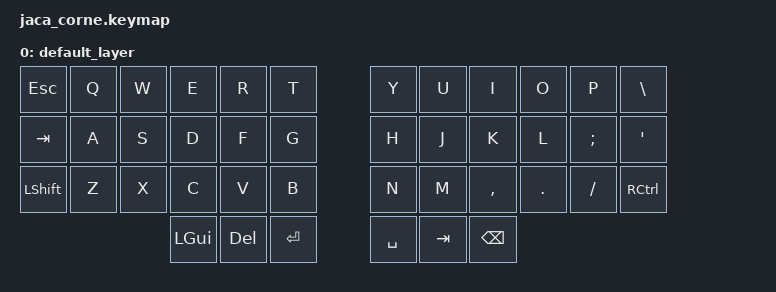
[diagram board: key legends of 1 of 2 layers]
#include <behaviors.dtsi>
#include <dt-bindings/zmk/keys.h>
#include <dt-bindings/zmk/bt.h>

/ {
    keymap {
        compatible = "zmk,keymap";

        default_layer {
// --------------------------------------------------------------------------------------------------------------------------------------------------------------------
// |   ESC   |    Q    |    W    |    E    |    R    |    T    |                               |    Y    |    U    |    I    |    O    |    P    |    \    |
// |   TAB   |    A    |    S    |    D    |    F    |    G    |                               |    H    |    J    |    K    |    L    |    ;    |    '    |
// |  SHIFT  |    Z    |    X    |    C    |    V    |    B    |                               |    N    |    M    |    ,    |    .    |    /    |  R CTRL |
//                               |   GUI   |   DEL   | RETURN  |                               |  SPACE  |   TAB   |   BSPC  |
            bindings = <
    &kp ESC    &kp Q    &kp W    &kp E     &kp R     &kp T                                     &kp Y     &kp U     &kp I     &kp O     &kp P    &kp BSLH
    &kp TAB    &kp A    &kp S    &kp D     &kp F     &kp G                                     &kp H     &kp J     &kp K     &kp L     &kp SEMI &kp SQT
    &kp LSHIFT &kp Z    &kp X    &kp C     &kp V     &kp B                                     &kp N     &kp M     &kp COMMA &kp DOT   &kp FSLH &kp RCTRL
                                 &kp LGUI  &kp DEL   &kp RET                                   &kp SPACE &kp TAB   &kp BSPC
            >;
        };

        bt_layer {
            bindings = <
    &none   &none   &none   &none   &none   &bootloader
    &none   &none   &none   &none   &none   &bt BT_CLR
    &none   &none   &none   &bt BT_SEL 2    &bt BT_SEL 1    &bt BT_SEL 0
            >;
        };

    };
};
